AUTOSAR XML (schema 4-2-2)
standard types defined: uint16
package /Acme/Chassis/DataTypes
  impl type SensorValue_impl: category=VALUE, base-type=uint16
package /Acme/Chassis/Interfaces
  sender receiver interface ISensorValue
    data value: type=SensorValue_impl
package /Acme/Chassis/Components
  application sw component type SensorSwc
    provide port pValue: provided-interface=ISensorValue
    behavior SensorSwc_InternalBehavior: handle-termination-and-restart=NO-SUPPORT
  application sw component type ActuatorSwc
    require port rValue: required-interface=ISensorValue
    behavior ActuatorSwc_InternalBehavior: handle-termination-and-restart=NO-SUPPORT
package /Acme/Chassis/Compositions
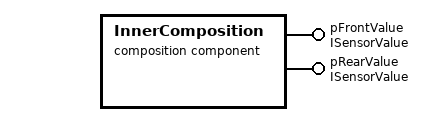
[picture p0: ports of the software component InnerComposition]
  composition sw component type InnerComposition
    provide port pFrontValue: provided-interface=ISensorValue
    provide port pRearValue: provided-interface=ISensorValue
    component SensorSwc_Front: type=SensorSwc
    component SensorSwc_Rear: type=SensorSwc
    delegate SensorSwc_Front.pValue <-> outer port pFrontValue
    delegate SensorSwc_Rear.pValueGhost <-> outer port pRearValue
  composition sw component type OuterComposition
    component InnerComposition_1: type=InnerComposition
    component ActuatorSwc_1: type=ActuatorSwc
    connect InnerComposition_1.pFrontValue -> ActuatorSwc_1.rValue
